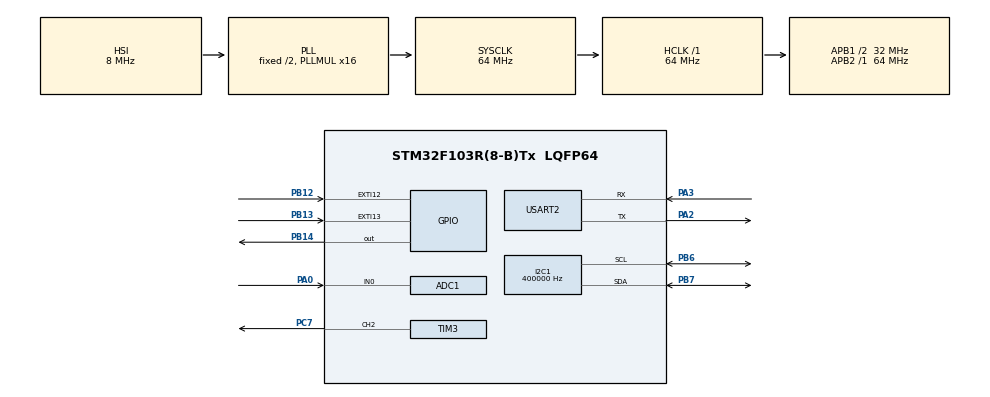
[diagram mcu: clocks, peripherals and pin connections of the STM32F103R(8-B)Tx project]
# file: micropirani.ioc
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ADC1.Channel-25\#ChannelRegularConversion=ADC_CHANNEL_0
ADC1.ContinuousConvMode=DISABLE
ADC1.NbrOfConversion=1
ADC1.NbrOfConversionFlag=1
ADC1.Rank-25\#ChannelRegularConversion=1
ADC1.SamplingTime-25\#ChannelRegularConversion=ADC_SAMPLETIME_1CYCLE_5
ADC1.master=1
I2C1.ClockSpeed=400000
I2C1.I2C_Mode=I2C_Fast
Mcu.Family=STM32F1
Mcu.Name=STM32F103R(8-B)Tx
Mcu.Package=LQFP64
NVIC.ADC1_2_IRQn=true\:0\:0\:false\:false\:true\:true\:true\:true
NVIC.EXTI15_10_IRQn=true\:0\:0\:false\:false\:true\:true\:true\:true
NVIC.PriorityGroup=NVIC_PRIORITYGROUP_4
NVIC.TIM1_UP_IRQn=true\:0\:0\:false\:false\:true\:true\:true\:true
NVIC.TIM2_IRQn=true\:0\:0\:false\:false\:true\:true\:true\:true
PA0-WKUP.Signal=ADCx_IN0
PA13.Mode=Serial_Wire
PA13.Signal=SYS_JTMS-SWDIO
PA14.Mode=Serial_Wire
PA14.Signal=SYS_JTCK-SWCLK
PA2.Mode=Asynchronous
PA2.Signal=USART2_TX
PA3.Mode=Asynchronous
PA3.Signal=USART2_RX
PB12.GPIO_ModeDefaultEXTI=GPIO_MODE_IT_FALLING
PB12.GPIO_PuPd=GPIO_PULLDOWN
PB12.Signal=GPXTI12
PB13.GPIO_ModeDefaultEXTI=GPIO_MODE_IT_RISING
PB13.GPIO_PuPd=GPIO_PULLDOWN
PB13.Signal=GPXTI13
PB14.Signal=GPIO_Output
PB6.Mode=I2C
PB6.Signal=I2C1_SCL
PB7.Mode=I2C
PB7.Signal=I2C1_SDA
PC7.Signal=S_TIM3_CH2
ProjectManager.HeapSize=0x200
ProjectManager.StackSize=0x400
ProjectManager.TargetToolchain=STM32CubeIDE
RCC.ADCPresc=RCC_ADCPCLK2_DIV8
RCC.AHBFreq_Value=64000000
RCC.APB1CLKDivider=RCC_HCLK_DIV2
RCC.APB1Freq_Value=32000000
RCC.APB1TimFreq_Value=64000000
RCC.APB2Freq_Value=64000000
RCC.APB2TimFreq_Value=64000000
RCC.HCLKFreq_Value=64000000
RCC.PLLMUL=RCC_PLL_MUL16
RCC.RTCClockSelection=RCC_RTCCLKSOURCE_LSE
RCC.SYSCLKFreq_VALUE=64000000
RCC.SYSCLKSource=RCC_SYSCLKSOURCE_PLLCLK
RCC.USBFreq_Value=64000000
SH.ADCx_IN0.0=ADC1_IN0,IN0
SH.S_TIM3_CH2.0=TIM3_CH2,PWM Generation2 CH2
TIM1.AutoReloadPreload=TIM_AUTORELOAD_PRELOAD_DISABLE
TIM1.ClockDivision=TIM_CLOCKDIVISION_DIV1
TIM1.Period=499
TIM1.Prescaler=1449
TIM2.ClockDivision=TIM_CLOCKDIVISION_DIV1
TIM2.Period=1
TIM2.Prescaler=64000
TIM3.Channel-PWM\ Generation2\ CH2=TIM_CHANNEL_2
TIM3.Period=3000
TIM3.Prescaler=1
TIM3.Pulse-PWM\ Generation2\ CH2=1500
USART2.VirtualMode=VM_ASYNC
VP_TIM1_VS_ClockSourceINT.Mode=Internal
VP_TIM2_VS_ClockSourceINT.Mode=Internal
board=NUCLEO-F103RB

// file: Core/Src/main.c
/* USER CODE BEGIN Header */
/**
  ******************************************************************************
  * @file           : main.c
  * @brief          : Main program body
  ******************************************************************************
  * @attention
  *
  * <h2><center>&copy; Copyright (c) 2024 STMicroelectronics.
  * All rights reserved.</center></h2>
  *
  * This software component is licensed by ST under BSD 3-Clause license,
  * the "License"; You may not use this file except in compliance with the
  * License. You may obtain a copy of the License at:
  *                        opensource.org/licenses/BSD-3-Clause
  *
  ******************************************************************************
  */
/* USER CODE END Header */
#include "main.h"

/* USER CODE BEGIN Includes */
#include "source/micropirani.h"
/* USER CODE END Includes */

ADC_HandleTypeDef hadc1;

I2C_HandleTypeDef hi2c1;

TIM_HandleTypeDef htim1;
TIM_HandleTypeDef htim2;
TIM_HandleTypeDef htim3;

UART_HandleTypeDef huart2;

void SystemClock_Config(void);
static void MX_GPIO_Init(void);
static void MX_TIM1_Init(void);
static void MX_ADC1_Init(void);
static void MX_TIM2_Init(void);
static void MX_I2C1_Init(void);
static void MX_TIM3_Init(void);
static void MX_USART2_UART_Init(void);

int main(void)
{

  /* MCU Configuration--------------------------------------------------------*/

  /* Reset of all peripherals, Initializes the Flash interface and the Systick. */
  HAL_Init();

  /* Configure the system clock */
  SystemClock_Config();

  /* Initialize all configured peripherals */
  MX_GPIO_Init();
  MX_TIM1_Init();
  MX_ADC1_Init();
  MX_TIM2_Init();
  MX_I2C1_Init();
  MX_TIM3_Init();
  MX_USART2_UART_Init();

  /* Infinite loop */
  while (1)
  {

  }
}

void SystemClock_Config(void)
{
  RCC_OscInitTypeDef RCC_OscInitStruct = {0};
  RCC_ClkInitTypeDef RCC_ClkInitStruct = {0};
  RCC_PeriphCLKInitTypeDef PeriphClkInit = {0};

  /** Initializes the RCC Oscillators according to the specified parameters
  * in the RCC_OscInitTypeDef structure.
  */
  RCC_OscInitStruct.OscillatorType = RCC_OSCILLATORTYPE_HSI;
  RCC_OscInitStruct.HSIState = RCC_HSI_ON;
  RCC_OscInitStruct.HSICalibrationValue = RCC_HSICALIBRATION_DEFAULT;
  RCC_OscInitStruct.PLL.PLLState = RCC_PLL_ON;
  RCC_OscInitStruct.PLL.PLLSource = RCC_PLLSOURCE_HSI_DIV2;
  RCC_OscInitStruct.PLL.PLLMUL = RCC_PLL_MUL16;
  if (HAL_RCC_OscConfig(&RCC_OscInitStruct) != HAL_OK)
  {
    Error_Handler();
  }
  /** Initializes the CPU, AHB and APB buses clocks
  */
  RCC_ClkInitStruct.ClockType = RCC_CLOCKTYPE_HCLK|RCC_CLOCKTYPE_SYSCLK
                              |RCC_CLOCKTYPE_PCLK1|RCC_CLOCKTYPE_PCLK2;
  RCC_ClkInitStruct.SYSCLKSource = RCC_SYSCLKSOURCE_PLLCLK;
  RCC_ClkInitStruct.AHBCLKDivider = RCC_SYSCLK_DIV1;
  RCC_ClkInitStruct.APB1CLKDivider = RCC_HCLK_DIV2;
  RCC_ClkInitStruct.APB2CLKDivider = RCC_HCLK_DIV1;

  if (HAL_RCC_ClockConfig(&RCC_ClkInitStruct, FLASH_LATENCY_2) != HAL_OK)
  {
    Error_Handler();
  }
  PeriphClkInit.PeriphClockSelection = RCC_PERIPHCLK_ADC;
  PeriphClkInit.AdcClockSelection = RCC_ADCPCLK2_DIV8;
  if (HAL_RCCEx_PeriphCLKConfig(&PeriphClkInit) != HAL_OK)
  {
    Error_Handler();
  }
}

static void MX_ADC1_Init(void)
{

  ADC_ChannelConfTypeDef sConfig = {0};

  /** Common config
  */
  hadc1.Instance = ADC1;
  hadc1.Init.ScanConvMode = ADC_SCAN_DISABLE;
  hadc1.Init.ContinuousConvMode = DISABLE;
  hadc1.Init.DiscontinuousConvMode = DISABLE;
  hadc1.Init.ExternalTrigConv = ADC_SOFTWARE_START;
  hadc1.Init.DataAlign = ADC_DATAALIGN_RIGHT;
  hadc1.Init.NbrOfConversion = 1;
  if (HAL_ADC_Init(&hadc1) != HAL_OK)
  {
    Error_Handler();
  }
  /** Configure Regular Channel
  */
  sConfig.Channel = ADC_CHANNEL_0;
  sConfig.Rank = ADC_REGULAR_RANK_1;
  sConfig.SamplingTime = ADC_SAMPLETIME_1CYCLE_5;
  if (HAL_ADC_ConfigChannel(&hadc1, &sConfig) != HAL_OK)
  {
    Error_Handler();
  }

}

static void MX_I2C1_Init(void)
{

  hi2c1.Instance = I2C1;
  hi2c1.Init.ClockSpeed = 400000;
  hi2c1.Init.DutyCycle = I2C_DUTYCYCLE_2;
  hi2c1.Init.OwnAddress1 = 0;
  hi2c1.Init.AddressingMode = I2C_ADDRESSINGMODE_7BIT;
  hi2c1.Init.DualAddressMode = I2C_DUALADDRESS_DISABLE;
  hi2c1.Init.OwnAddress2 = 0;
  hi2c1.Init.GeneralCallMode = I2C_GENERALCALL_DISABLE;
  hi2c1.Init.NoStretchMode = I2C_NOSTRETCH_DISABLE;
  if (HAL_I2C_Init(&hi2c1) != HAL_OK)
  {
    Error_Handler();
  }

}

static void MX_TIM1_Init(void)
{

  TIM_ClockConfigTypeDef sClockSourceConfig = {0};
  TIM_MasterConfigTypeDef sMasterConfig = {0};

  htim1.Instance = TIM1;
  htim1.Init.Prescaler = 1449;
  htim1.Init.CounterMode = TIM_COUNTERMODE_UP;
  htim1.Init.Period = 499;
  htim1.Init.ClockDivision = TIM_CLOCKDIVISION_DIV1;
  htim1.Init.RepetitionCounter = 0;
  htim1.Init.AutoReloadPreload = TIM_AUTORELOAD_PRELOAD_DISABLE;
  if (HAL_TIM_Base_Init(&htim1) != HAL_OK)
  {
    Error_Handler();
  }
  sClockSourceConfig.ClockSource = TIM_CLOCKSOURCE_INTERNAL;
  if (HAL_TIM_ConfigClockSource(&htim1, &sClockSourceConfig) != HAL_OK)
  {
    Error_Handler();
  }
  sMasterConfig.MasterOutputTrigger = TIM_TRGO_RESET;
  sMasterConfig.MasterSlaveMode = TIM_MASTERSLAVEMODE_DISABLE;
  if (HAL_TIMEx_MasterConfigSynchronization(&htim1, &sMasterConfig) != HAL_OK)
  {
    Error_Handler();
  }

}

static void MX_TIM2_Init(void)
{

  TIM_ClockConfigTypeDef sClockSourceConfig = {0};
  TIM_MasterConfigTypeDef sMasterConfig = {0};

  htim2.Instance = TIM2;
  htim2.Init.Prescaler = 64000;
  htim2.Init.CounterMode = TIM_COUNTERMODE_UP;
  htim2.Init.Period = 1;
  htim2.Init.ClockDivision = TIM_CLOCKDIVISION_DIV1;
  htim2.Init.AutoReloadPreload = TIM_AUTORELOAD_PRELOAD_DISABLE;
  if (HAL_TIM_Base_Init(&htim2) != HAL_OK)
  {
    Error_Handler();
  }
  sClockSourceConfig.ClockSource = TIM_CLOCKSOURCE_INTERNAL;
  if (HAL_TIM_ConfigClockSource(&htim2, &sClockSourceConfig) != HAL_OK)
  {
    Error_Handler();
  }
  sMasterConfig.MasterOutputTrigger = TIM_TRGO_RESET;
  sMasterConfig.MasterSlaveMode = TIM_MASTERSLAVEMODE_DISABLE;
  if (HAL_TIMEx_MasterConfigSynchronization(&htim2, &sMasterConfig) != HAL_OK)
  {
    Error_Handler();
  }

}

static void MX_TIM3_Init(void)
{

  TIM_MasterConfigTypeDef sMasterConfig = {0};
  TIM_OC_InitTypeDef sConfigOC = {0};

  htim3.Instance = TIM3;
  htim3.Init.Prescaler = 1;
  htim3.Init.CounterMode = TIM_COUNTERMODE_UP;
  htim3.Init.Period = 3000;
  htim3.Init.ClockDivision = TIM_CLOCKDIVISION_DIV1;
  htim3.Init.AutoReloadPreload = TIM_AUTORELOAD_PRELOAD_DISABLE;
  if (HAL_TIM_PWM_Init(&htim3) != HAL_OK)
  {
    Error_Handler();
  }
  sMasterConfig.MasterOutputTrigger = TIM_TRGO_RESET;
  sMasterConfig.MasterSlaveMode = TIM_MASTERSLAVEMODE_DISABLE;
  if (HAL_TIMEx_MasterConfigSynchronization(&htim3, &sMasterConfig) != HAL_OK)
  {
    Error_Handler();
  }
  sConfigOC.OCMode = TIM_OCMODE_PWM1;
  sConfigOC.Pulse = 1500;
  sConfigOC.OCPolarity = TIM_OCPOLARITY_HIGH;
  sConfigOC.OCFastMode = TIM_OCFAST_DISABLE;
  if (HAL_TIM_PWM_ConfigChannel(&htim3, &sConfigOC, TIM_CHANNEL_2) != HAL_OK)
  {
    Error_Handler();
  }
  HAL_TIM_MspPostInit(&htim3);

}

static void MX_USART2_UART_Init(void)
{

  huart2.Instance = USART2;
  huart2.Init.BaudRate = 115200;
  huart2.Init.WordLength = UART_WORDLENGTH_8B;
  huart2.Init.StopBits = UART_STOPBITS_1;
  huart2.Init.Parity = UART_PARITY_NONE;
  huart2.Init.Mode = UART_MODE_TX_RX;
  huart2.Init.HwFlowCtl = UART_HWCONTROL_NONE;
  huart2.Init.OverSampling = UART_OVERSAMPLING_16;
  if (HAL_UART_Init(&huart2) != HAL_OK)
  {
    Error_Handler();
  }

}

static void MX_GPIO_Init(void)
{
  GPIO_InitTypeDef GPIO_InitStruct = {0};

  /* GPIO Ports Clock Enable */
  __HAL_RCC_GPIOA_CLK_ENABLE();
  __HAL_RCC_GPIOB_CLK_ENABLE();
  __HAL_RCC_GPIOC_CLK_ENABLE();

  /*Configure GPIO pin Output Level */
  HAL_GPIO_WritePin(GPIOB, GPIO_PIN_14, GPIO_PIN_RESET);

  /*Configure GPIO pin : PB12 */
  GPIO_InitStruct.Pin = GPIO_PIN_12;
  GPIO_InitStruct.Mode = GPIO_MODE_IT_FALLING;
  GPIO_InitStruct.Pull = GPIO_PULLDOWN;
  HAL_GPIO_Init(GPIOB, &GPIO_InitStruct);

  /*Configure GPIO pin : PB13 */
  GPIO_InitStruct.Pin = GPIO_PIN_13;
  GPIO_InitStruct.Mode = GPIO_MODE_IT_RISING;
  GPIO_InitStruct.Pull = GPIO_PULLDOWN;
  HAL_GPIO_Init(GPIOB, &GPIO_InitStruct);

  /*Configure GPIO pin : PB14 */
  GPIO_InitStruct.Pin = GPIO_PIN_14;
  GPIO_InitStruct.Mode = GPIO_MODE_OUTPUT_PP;
  GPIO_InitStruct.Pull = GPIO_NOPULL;
  GPIO_InitStruct.Speed = GPIO_SPEED_FREQ_LOW;
  HAL_GPIO_Init(GPIOB, &GPIO_InitStruct);

  /* EXTI interrupt init*/
  HAL_NVIC_SetPriority(EXTI15_10_IRQn, 0, 0);
  HAL_NVIC_EnableIRQ(EXTI15_10_IRQn);

}

void Error_Handler(void)
{
  __disable_irq();
  while (1)
  {
  }
}

/************************ (C) COPYRIGHT STMicroelectronics *****END OF FILE****/
